# XMC1400 register map
Vendor: Infineon; File version: 1.0.3 (Reference Manual v0.1)
CPU: CM0 r0p0, little endian, no MPU, no FPU, 2 interrupt priority bits
Registers are 32-bit, read-write, reset 0x0 unless marked. A register's access mark holds for its fields unless they carry their own. Offsets are from the block's base; [hi:lo] are bit positions; {n}, {i} and the like mark numbered series; 'fields as' and 'values as' point back to an identical list.

## BCCU0_CH0 — BCCU Unit 0
Base 0x5003003C
Same registers: BCCU0_CH{n} {0x5003003C+0x14*n} (n=1..8)
0x00 INTS — Channel Intensit0 Shadow
  [11:0] TCHINT — Target Channel Intensity
0x04 INT ro — Channel Intensit0
  [11:0] CHINT — Channel Intensity
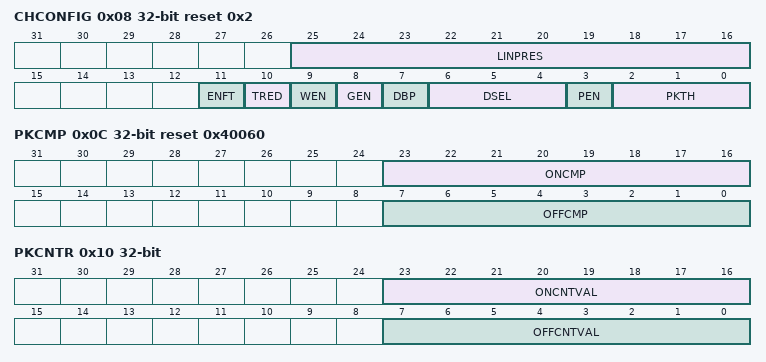
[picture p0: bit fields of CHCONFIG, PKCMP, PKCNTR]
0x08 CHCONFIG reset 0x2 — Channel Configuration
  [25:16] LINPRES — Linear Walker Clock Prescaler
  [11] ENFT — Forced Trigger Enable
    0=No forced trigger is generated; 1=The trigger generator generates a trigger if the output of the sigma-delta modulator hasn't changed state for 256 bit times; only takes effect if the packer is disabled (PEN=0)
  [10] TRED — Trigger Edge
    0=Channel triggers occur on channel output transition from passive to active level; 1=Channel triggers occur on channel output transition from active to passive level
  [9] WEN — Flicker Watchdog Enable
    0=The flicker watchdog is not used; 1=The flicker watchdog is active and limits the number of consecutive zeroes at the sigma-delta modulator output according to GLOBCON.WDMBN
  [8] GEN — Gating Enable
    0=Gating function is disabled, the input signal (BCCU.INy) has no effect; 1=Gating function is enabled, the output gating signal is BCCU.INy
  [7] DBP — Dimming Input Bypass
    0=Channel brightness is the product of the selected dimming input and the channel intensity; 1=No dimming input is used, channel brightness is only determined by the channel intensity level
  [6:4] DSEL — Dimming Select
    0=Dimming Engine 0; 1=Dimming Engine 1; 2=Dimming Engine 2; 7=Global Dimming Level
  [3] PEN — Packer Enable
    0=The packer is not used; 1=On-time and off-time counters are running and the packed output bitstream with the packer trigger are generated
  [2:0] PKTH — Packer Threshold
    0=Not allowed; {v}=Threshold value of {v} (v=1..4)
0x0C PKCMP reset 0x40060 — Packer Compare
  [23:16] ONCMP — Packer On-Time Compare Level
  [7:0] OFFCMP — Packer Off-Time Compare Level
0x10 PKCNTR — Packer Counter
  [23:16] ONCNTVAL — On-Time Counter Value
  [7:0] OFFCNTVAL — Off-Time Counter Value

## BCCU0_DE0 — BCCU Unit 0
Base 0x5003017C
Same registers: BCCU0_DE1 0x50030188, BCCU0_DE2 0x50030194
0x00 DLS — Dimming Level Shadow
  [11:0] TDLEV — Target Dimming Level
0x04 DL ro — Dimming Level
  [11:0] DLEV
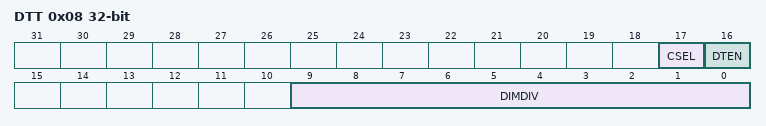
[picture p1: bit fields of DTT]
0x08 DTT — Dimming Transition Time
  [17] CSEL — Curve Select
    0=Coarse curve; 1=Fine curve
  [16] DTEN — Dither Enable
    0=No dithering; 1=Dithering is added to every dimming step if the dimming level is below 128; the coarse curve is used for the entire dimming range
  [9:0] DIMDIV — Dimming Clock Divider

## PORT0
Base 0x40040000
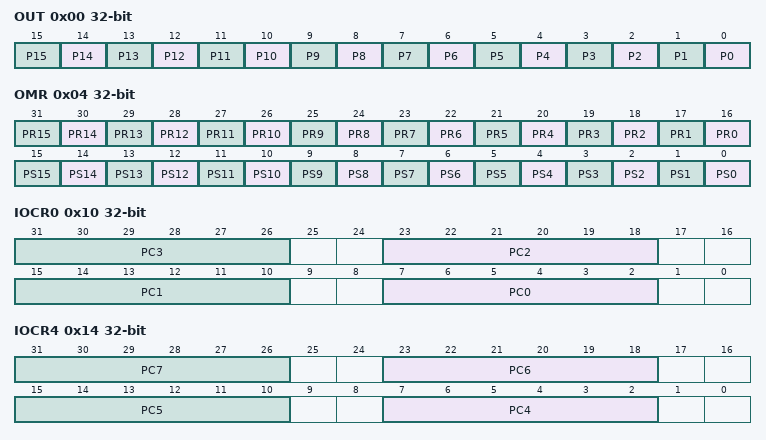
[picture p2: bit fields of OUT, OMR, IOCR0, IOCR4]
0x00 OUT — Port 0 Output Register
  [all] fields
    0=The output level of P0.x is 0; 1=The output level of P0.x is 1
  [n] P{n} (n=0..15) — Port 0 Output Bit {n}
0x04 OMR wo — Port 0 Output Modification Register
  [n+16] PR{n} (n=0..15) — Port 0 Reset Bit {n}
  [n] PS{n} (n=0..15) — Port 0 Set Bit {n}
0x10 IOCR0 — Port 0 Input/Output Control Register 0
  [all] fields
    0=Input - No internal pull device active; 1=Input - Internal pull-down device active; 2=Input - Internal pull-up device active; 3=Input - No internal pull device, Pn_OUTx = input value; 4=Input inverted - No internal pull device active; 5=Input inverted - Internal pull-down device active; 6=Input inverted - Internal pull-up device active; 7=Input inverted - No internal pull device, Pn_OUTx = input value; 32=Output Push-Pull - General-purpose output; {v}=Output Push-Pull - Alternate output function {v-32} (v=33..41); 48=Output Open Drain - General-purpose output; {v}=Output Open Drain - Alternate output function {v-48} (v=49..57)
  [8n+7:8n+2] PC{n} (n=0..3) — Port Control for Port n Pin 0 to 3
0x14 IOCR4 — Port 0 Input/Output Control Register 4
  [all] fields
    values as the fields of IOCR0
  [8n-25:8n-30] PC{n} (n=4..7) — Port Control for Port n Pin 4 to 7
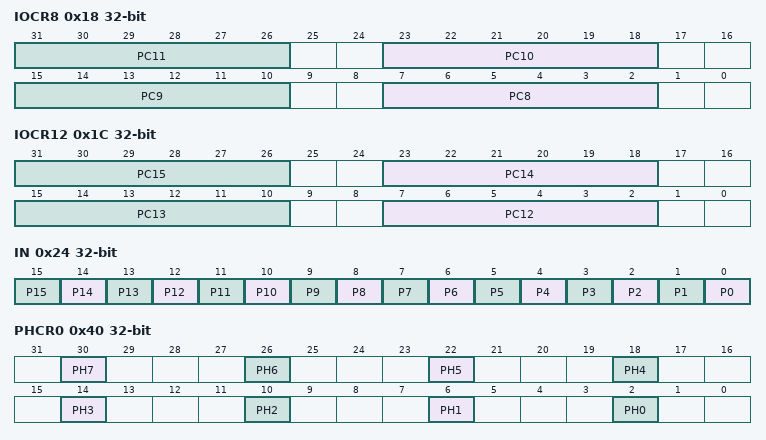
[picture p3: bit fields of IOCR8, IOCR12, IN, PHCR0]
0x18 IOCR8 — Port 0 Input/Output Control Register 8
  [all] fields
    values as the fields of IOCR0
  [8n-57:8n-62] PC{n} (n=8..11) — Port Control for Port n Pin 8 to 11
0x1C IOCR12 — Port 0 Input/Output Control Register 12
  [all] fields
    values as the fields of IOCR0
  [8n-89:8n-94] PC{n} (n=12..15) — Port Control for Port n Pin 12 to 15
0x24 IN ro (reset mask 0xFFFF0000) — Port 0 Input Register
  [all] fields
    0=The input level of P0.x is 0; 1=The input level of P0.x is 1
  [n] P{n} (n=0..15) — Port 0 Input Bit {n}
0x40 PHCR0 — Port 0 Pad Hysteresis Control Register 0
  [30] PH7 — Pad Hysteresis for Pn.7
  [26] PH6 — Pad Hysteresis for Pn.6
  [22] PH5 — Pad Hysteresis for Pn.5
  [18] PH4 — Pad Hysteresis for Pn.4
  [14] PH3 — Pad Hysteresis for Pn.3
  [10] PH2 — Pad Hysteresis for Pn.2
  [6] PH1 — Pad Hysteresis for Pn.1
  [2] PH0 — Pad Hysteresis for Pn.0
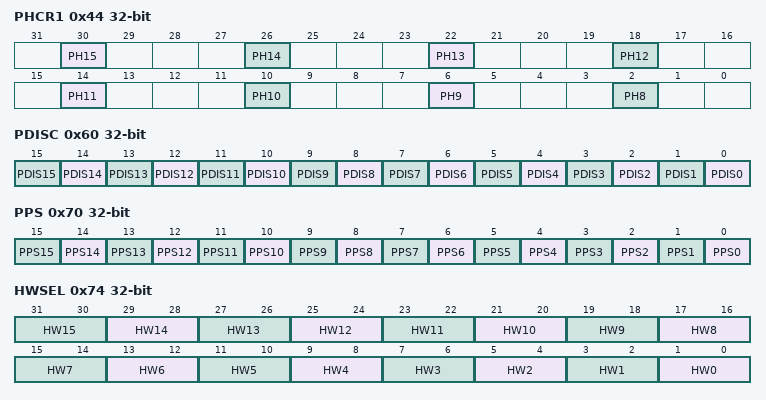
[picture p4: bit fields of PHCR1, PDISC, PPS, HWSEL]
0x44 PHCR1 — Port 0 Pad Hysteresis Control Register 1
  [30] PH15 — Pad Hysteresis for P0.15
  [26] PH14 — Pad Hysteresis for P0.14
  [22] PH13 — Pad Hysteresis for P0.13
  [18] PH12 — Pad Hysteresis for P0.12
  [14] PH11 — Pad Hysteresis for P0.11
  [10] PH10 — Pad Hysteresis for P0.10
  [6] PH9 — Pad Hysteresis for P0.9
  [2] PH8 — Pad Hysteresis for P0.8
0x60 PDISC ro (reset mask 0xFFFF0000) — Port 0 Pin Function Decision Control Register
  [all] fields
    0=Pad P0.x is enabled; 1=Pad P0.x is disabled
  [n] PDIS{n} (n=0..15) — Pad Disable for Port 0 Pin {n}
0x70 PPS — Port 0 Pin Power Save Register
  [all] fields
    0=Pin Power Save of P0.x is disabled; 1=Pin Power Save of P0.x is enabled
  [n] PPS{n} (n=0..15) — Port 0 Pin Power Save Bit {n}
0x74 HWSEL — Port 0 Pin Hardware Select Register
  [all] fields
    0=Software control only; 1=HW0 control path can override the software configuration; 2=HW1 control path can override the software configuration
  [2n+1:2n] HW{n} (n=0..15) — Port 0 Pin Hardware Select Bit {n}
